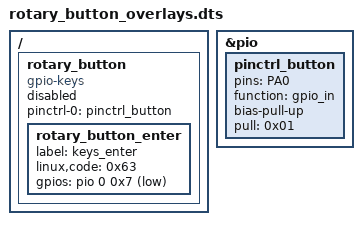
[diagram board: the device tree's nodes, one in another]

&pio {
	pinctrl_button: pinctrl_button {
		pins = "PA0";
		function = "gpio_in";
		bias-pull-up;
		pull = <0x01>;
	};
};

/ {
	rotary_button {
		compatible = "gpio-keys";
		pinctrl-names = "default";
		pinctrl-0 = <&pinctrl_button>;
		status = "disabled";

		rotary_button_enter {
			label = "keys_enter";
			linux,code = <0x63>;
			gpios = <&pio 0 0x7 0x01>;
		};
	};
};

